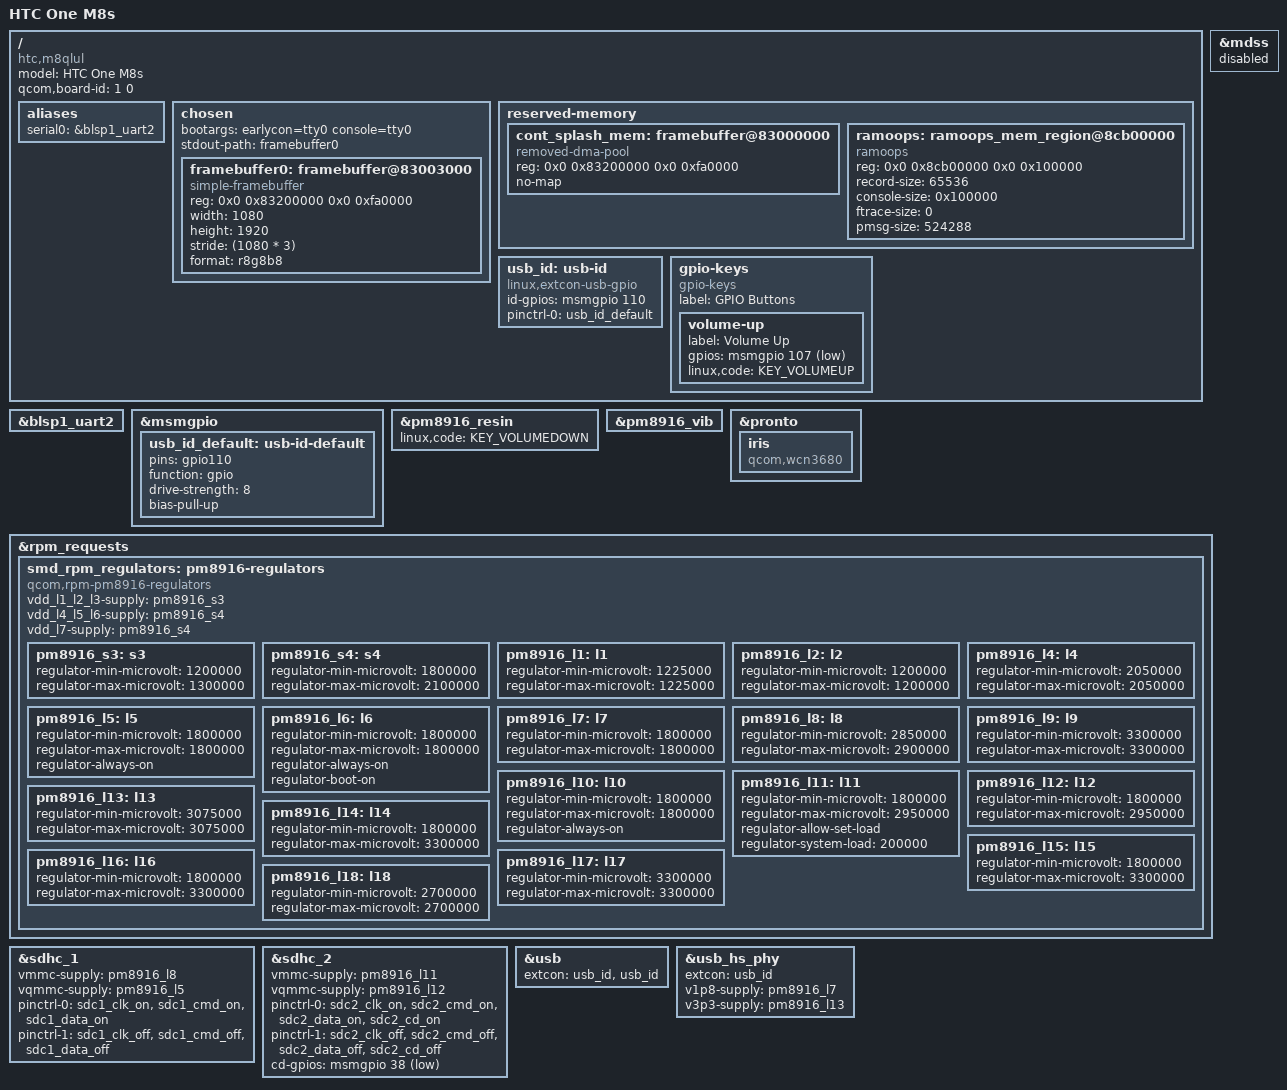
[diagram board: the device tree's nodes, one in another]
// SPDX-License-Identifier: GPL-2.0-only

/dts-v1/;

#include "msm8939.dtsi"
#include "pm8916.dtsi"
#include "arm/qcom-msm8939-no-psci.dtsi"
#include <dt-bindings/gpio/gpio.h>

/ {
	model = "HTC One M8s";
	compatible = "htc,m8qlul", "qcom,msm8939";
	qcom,board-id = <1 0>;

	aliases {
		serial0 = &blsp1_uart2;
	};

	chosen {
		bootargs = "earlycon=tty0 console=tty0";
		stdout-path = "framebuffer0";

		#address-cells = <2>;
		#size-cells = <2>;
		ranges;

		framebuffer0: framebuffer@83003000 {
			status= "okay";
			compatible = "simple-framebuffer";
			reg = <0x0 0x83200000 0x0 0xfa0000>;
			width = <1080>;
			height = <1920>;
			stride = <(1080 * 3)>;
			format = "r8g8b8";
		};
	};

	reserved-memory {
		#address-cells = <2>;
		#size-cells = <2>;
		ranges;

		cont_splash_mem: framebuffer@83000000 {
                        compatible = "removed-dma-pool";
                        reg = <0x0 0x83200000 0x0 0xfa0000>;
                        no-map;
                };

		ramoops: ramoops_mem_region@8cb00000 {
			compatible = "ramoops";
			reg = <0x0 0x8cb00000 0x0 0x100000>;

			record-size = <65536>;
                        console-size = <0x100000>;
                        ftrace-size = <0>;
                        pmsg-size = <524288>;
		};
	};

	usb_id: usb-id {
		compatible = "linux,extcon-usb-gpio";
		id-gpios = <&msmgpio 110 0>; // FIXME; 0 = GPIO_ACTIVE_HIGH?
		pinctrl-names = "default";
		pinctrl-0 = <&usb_id_default>;
	};

	gpio-keys {
		compatible = "gpio-keys";

		pinctrl-names = "default";

		label = "GPIO Buttons";

		volume-up {
			label = "Volume Up";
			gpios = <&msmgpio 107 GPIO_ACTIVE_LOW>;
			linux,code = <KEY_VOLUMEUP>;
		};
	};
};

&blsp1_uart2 {
	status = "okay";
};

&mdss {
	status = "disabled";
};

&msmgpio {
	usb_id_default: usb-id-default {
		pins = "gpio110";
		function = "gpio";

		drive-strength = <8>;
		bias-pull-up;
	};
};

&pm8916_resin {
	status = "okay";
	linux,code = <KEY_VOLUMEDOWN>;
};

&pm8916_vib {
	status = "okay";
};

&pronto {
	status = "okay";

	iris {
		compatible = "qcom,wcn3680";
	};
};

&rpm_requests {
	smd_rpm_regulators: pm8916-regulators {
		compatible = "qcom,rpm-pm8916-regulators";
		vdd_l1_l2_l3-supply = <&pm8916_s3>;
		vdd_l4_l5_l6-supply = <&pm8916_s4>;
		vdd_l7-supply = <&pm8916_s4>;

		pm8916_s3: s3 { // ok
			regulator-min-microvolt = <1200000>;
			regulator-max-microvolt = <1300000>;
		};

		pm8916_s4: s4 { // ok
			regulator-min-microvolt = <1800000>;
			regulator-max-microvolt = <2100000>;
		};

		pm8916_l1: l1 { // ok
			regulator-min-microvolt = <1225000>;
			regulator-max-microvolt = <1225000>;
		};

		pm8916_l2: l2 { // ok
			regulator-min-microvolt = <1200000>;
			regulator-max-microvolt = <1200000>;
		};

		pm8916_l4: l4 { // ok
			regulator-min-microvolt = <2050000>;
			regulator-max-microvolt = <2050000>;
		};

		pm8916_l5: l5 { // ok
			regulator-min-microvolt = <1800000>;
			regulator-max-microvolt = <1800000>;
			regulator-always-on;
		};

		pm8916_l6: l6 { // ok
			regulator-min-microvolt = <1800000>;
			regulator-max-microvolt = <1800000>;
			regulator-always-on;
			regulator-boot-on;
		};

		pm8916_l7: l7 { // ok
			regulator-min-microvolt = <1800000>;
			regulator-max-microvolt = <1800000>;
		};

		pm8916_l8: l8 { // ok
			regulator-min-microvolt = <2850000>;
			regulator-max-microvolt = <2900000>;
		};

		pm8916_l9: l9 { // ok
			regulator-min-microvolt = <3300000>;
			regulator-max-microvolt = <3300000>;
		};

		pm8916_l10: l10 { // ok, didn't originally match downstream
			regulator-min-microvolt = <1800000>;
			regulator-max-microvolt = <1800000>;
			regulator-always-on; /* comment from downstream: V_AUD_1V8 need always on as audio request */
		};

		pm8916_l11: l11 { // ok!!
			regulator-min-microvolt = <1800000>;
			regulator-max-microvolt = <2950000>;
			regulator-allow-set-load;
			regulator-system-load = <200000>;
		};

		pm8916_l12: l12 { // ok
			regulator-min-microvolt = <1800000>;
			regulator-max-microvolt = <2950000>;
		};

		pm8916_l13: l13 { // ok
			regulator-min-microvolt = <3075000>;
			regulator-max-microvolt = <3075000>;
		};

		pm8916_l14: l14 { // ok
			regulator-min-microvolt = <1800000>;
			regulator-max-microvolt = <3300000>;
		};

		pm8916_l15: l15 { // ok
			regulator-min-microvolt = <1800000>;
			regulator-max-microvolt = <3300000>;
		};

		pm8916_l16: l16 { // ok
			regulator-min-microvolt = <1800000>;
			regulator-max-microvolt = <3300000>;
		};

		pm8916_l17: l17 { // ok, didn't originally match downstream
			regulator-min-microvolt = <3300000>;
			regulator-max-microvolt = <3300000>;
		};

		pm8916_l18: l18 { // ok
			regulator-min-microvolt = <2700000>;
			regulator-max-microvolt = <2700000>;
		};
	};
};

&sdhc_1 {
	status = "okay";

	vmmc-supply = <&pm8916_l8>;
	vqmmc-supply = <&pm8916_l5>;

	pinctrl-names = "default", "sleep";
	pinctrl-0 = <&sdc1_clk_on &sdc1_cmd_on &sdc1_data_on>;
	pinctrl-1 = <&sdc1_clk_off &sdc1_cmd_off &sdc1_data_off>;
};

&sdhc_2 {
	status = "okay";

	vmmc-supply = <&pm8916_l11>;
	vqmmc-supply = <&pm8916_l12>;

	pinctrl-names = "default", "sleep";
	pinctrl-0 = <&sdc2_clk_on &sdc2_cmd_on &sdc2_data_on &sdc2_cd_on>;
	pinctrl-1 = <&sdc2_clk_off &sdc2_cmd_off &sdc2_data_off &sdc2_cd_off>;

	cd-gpios = <&msmgpio 38 GPIO_ACTIVE_LOW>;
};

&usb {
	status = "okay";
	extcon = <&usb_id>, <&usb_id>;
};

&usb_hs_phy {
	extcon = <&usb_id>;
	v1p8-supply = <&pm8916_l7>;
        v3p3-supply = <&pm8916_l13>;
};
